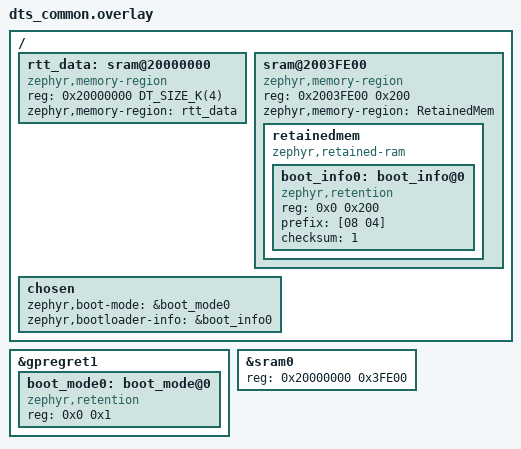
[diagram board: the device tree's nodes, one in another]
&gpregret1 {
        status = "okay";

        boot_mode0: boot_mode@0 {
                compatible = "zephyr,retention";
                status = "okay";
                reg = <0x0 0x1>;
        };
};

/ {
        /* Memory for Segger RTT buffers, must be the same for B0, MCUBoot, fw_loader and the main app */
        rtt_data: sram@20000000 {                         /* Label this node as 'shared_sram' */
            compatible = "zephyr,memory-region", "mmio-sram";
            reg = <0x20000000 DT_SIZE_K(4)>;                    /* Size 4 KiB */
            zephyr,memory-region = "rtt_data";                  /* Create a linker region named "rtt_data" */
            status = "okay";
        };
};

/ {
        sram@2003FE00 {
                compatible = "zephyr,memory-region", "mmio-sram";
                reg = <0x2003FE00 0x200>;
                zephyr,memory-region = "RetainedMem";
                status = "okay";

                retainedmem {
                        compatible = "zephyr,retained-ram";
                        status = "okay";
                        #address-cells = <1>;
                        #size-cells = <1>;

                        boot_info0: boot_info@0 {
                                compatible = "zephyr,retention";
                                status = "okay";
                                reg = <0x0 0x200>;
                                prefix = [08 04];
                                checksum = <1>;
                        };
                };
        };

        chosen {
                zephyr,boot-mode = &boot_mode0;
                zephyr,bootloader-info = &boot_info0;
        };
};

/* Reduce SRAM0 usage by 0x200 bytes to account for non-init area */
&sram0 {
        reg = <0x20000000 0x3FE00>;
};
